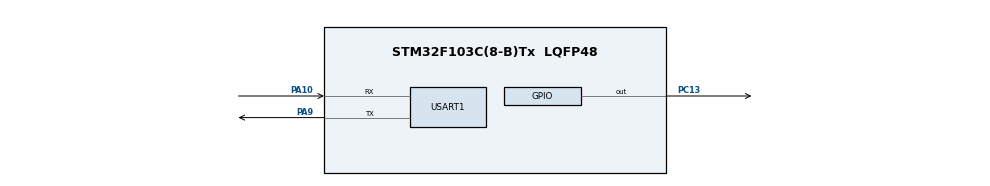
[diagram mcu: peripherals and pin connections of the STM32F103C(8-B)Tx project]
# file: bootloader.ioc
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Mcu.Family=STM32F1
Mcu.Name=STM32F103C(8-B)Tx
Mcu.Package=LQFP48
NVIC.PriorityGroup=NVIC_PRIORITYGROUP_4
PA10.Mode=Asynchronous
PA10.Signal=USART1_RX
PA13.Mode=Serial_Wire
PA13.Signal=SYS_JTMS-SWDIO
PA14.Mode=Serial_Wire
PA14.Signal=SYS_JTCK-SWCLK
PA9.Mode=Asynchronous
PA9.Signal=USART1_TX
PC13-TAMPER-RTC.Signal=GPIO_Output
ProjectManager.HeapSize=0x200
ProjectManager.StackSize=0x400
ProjectManager.TargetToolchain=Makefile
RCC.APB1Freq_Value=8000000
RCC.APB2Freq_Value=8000000
USART1.VirtualMode=VM_ASYNC
board=custom

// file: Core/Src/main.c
/* USER CODE BEGIN Header */
/**
 ******************************************************************************
 * @file           : main.c
 * @brief          : Main program body
 ******************************************************************************
 * @attention
 *
 * Copyright (c) 2026 STMicroelectronics.
 * All rights reserved.
 *
 * This software is licensed under terms that can be found in the LICENSE file
 * in the root directory of this software component.
 * If no LICENSE file comes with this software, it is provided AS-IS.
 *
 ******************************************************************************
 */
/* USER CODE END Header */
#include "main.h"

/* USER CODE BEGIN Includes */
#include "string.h"
/* USER CODE END Includes */

UART_HandleTypeDef huart1;

void SystemClock_Config(void);
static void MX_GPIO_Init(void);
static void MX_USART1_UART_Init(void);

/* USER CODE BEGIN 0 */
#define APP_PROGRAM_ADDRESS 0x08002000
typedef void (*pFunction)(void);

void enterApplication(void) {
    // uint32_t appStack = *(__IO uint32_t *)APP_PROGRAM_ADDRESS;
    pFunction appEntry = (pFunction)(*(__IO uint32_t *)(APP_PROGRAM_ADDRESS + 4));

    HAL_DeInit();
    HAL_RCC_DeInit();

    SCB->SHCSR &= ~(SCB_SHCSR_MEMFAULTENA_Msk | SCB_SHCSR_BUSFAULTENA_Msk | SCB_SHCSR_USGFAULTENA_Msk);

    __set_MSP(*(__IO uint32_t *)APP_PROGRAM_ADDRESS);

    appEntry();
}

uint16_t simpleChecksum(uint8_t *data, uint16_t length) {
    uint16_t checksum = 0;
    for (uint16_t i = 0; i < length; i++) {
        checksum += data[i];
    }
    return checksum;
}

#define START_PAGE 8
#define END_PAGE 127

#define START_BYTE 0xAA
#define ACK 0xCC
#define NACK 0x33
#define BLOCK_SIZE 256

void sendByte(uint8_t byte) {
    HAL_UART_Transmit(&huart1, &byte, 1, 1000);
}

uint8_t receiveByte(uint8_t *byteBuffer, uint16_t size, uint16_t timeout) {
    return HAL_UART_Receive(&huart1, byteBuffer, size, timeout);
}

uint8_t header[3];
uint8_t data[BLOCK_SIZE];
uint8_t checksum[2];

void bootloaderTask() {
    memset(header, 0, sizeof(header));
    uint32_t app_address = APP_PROGRAM_ADDRESS;

    // HAL_Delay(100000);
    flash_erase(APP_PROGRAM_ADDRESS, 50);
    // HAL_Delay(100000);
    while (1) {
        if (receiveByte(&header[0], 1, 5000) != HAL_OK || header[0] != START_BYTE)
            continue;
        if (receiveByte(&header[1], 2, 1000) != HAL_OK) {
            sendByte(NACK);
            continue;
        }

        uint16_t length = (header[1] << 8) | header[2];
        if (length > BLOCK_SIZE) {
            sendByte(NACK);
            continue;
        }

        if (length == 0) {
            sendByte(ACK);
            break;
        }

        if (receiveByte(data, length, 2000) != HAL_OK) {
            sendByte(NACK);
            continue;
        }

        if (receiveByte(checksum, 2, 1000) != HAL_OK) {
            sendByte(NACK);
            continue;
        }

        uint16_t receivedChecksum = (checksum[0] << 8) | checksum[1];
        uint16_t calculatedChecksum = simpleChecksum(data, length);
        if (receivedChecksum != calculatedChecksum) {
            sendByte(NACK);
            continue;
        }

        flash_write(app_address, data, length);
        app_address += length;

        sendByte(ACK);
    }
}

/* USER CODE END 0 */

int main(void)
{

  /* MCU Configuration--------------------------------------------------------*/

  /* Reset of all peripherals, Initializes the Flash interface and the Systick. */
  HAL_Init();

  /* Configure the system clock */
  SystemClock_Config();

  /* Initialize all configured peripherals */
  MX_GPIO_Init();
  MX_USART1_UART_Init();
  /* USER CODE BEGIN 2 */
    HAL_GPIO_WritePin(GPIOC, GPIO_PIN_13, GPIO_PIN_RESET);
    bootloaderTask();
    HAL_GPIO_WritePin(GPIOC, GPIO_PIN_13, GPIO_PIN_SET);
    enterApplication();
  /* USER CODE END 2 */

  /* Infinite loop */
  /* USER CODE BEGIN WHILE */
    while (1) {
        // HAL_GPIO_WritePin(GPIOC, GPIO_PIN_13, GPIO_PIN_RESET);
        // HAL_Delay(1000);

        // enterApplication();
        // HAL_Delay(100);
    /* USER CODE END WHILE */

    }
}

void SystemClock_Config(void)
{
  RCC_OscInitTypeDef RCC_OscInitStruct = {0};
  RCC_ClkInitTypeDef RCC_ClkInitStruct = {0};

  /** Initializes the RCC Oscillators according to the specified parameters
  * in the RCC_OscInitTypeDef structure.
  */
  RCC_OscInitStruct.OscillatorType = RCC_OSCILLATORTYPE_HSI;
  RCC_OscInitStruct.HSIState = RCC_HSI_ON;
  RCC_OscInitStruct.HSICalibrationValue = RCC_HSICALIBRATION_DEFAULT;
  RCC_OscInitStruct.PLL.PLLState = RCC_PLL_NONE;
  if (HAL_RCC_OscConfig(&RCC_OscInitStruct) != HAL_OK)
  {
    Error_Handler();
  }

  /** Initializes the CPU, AHB and APB buses clocks
  */
  RCC_ClkInitStruct.ClockType = RCC_CLOCKTYPE_HCLK|RCC_CLOCKTYPE_SYSCLK
                              |RCC_CLOCKTYPE_PCLK1|RCC_CLOCKTYPE_PCLK2;
  RCC_ClkInitStruct.SYSCLKSource = RCC_SYSCLKSOURCE_HSI;
  RCC_ClkInitStruct.AHBCLKDivider = RCC_SYSCLK_DIV1;
  RCC_ClkInitStruct.APB1CLKDivider = RCC_HCLK_DIV1;
  RCC_ClkInitStruct.APB2CLKDivider = RCC_HCLK_DIV1;

  if (HAL_RCC_ClockConfig(&RCC_ClkInitStruct, FLASH_LATENCY_0) != HAL_OK)
  {
    Error_Handler();
  }
}

static void MX_USART1_UART_Init(void)
{

  huart1.Instance = USART1;
  huart1.Init.BaudRate = 115200;
  huart1.Init.WordLength = UART_WORDLENGTH_8B;
  huart1.Init.StopBits = UART_STOPBITS_1;
  huart1.Init.Parity = UART_PARITY_NONE;
  huart1.Init.Mode = UART_MODE_TX_RX;
  huart1.Init.HwFlowCtl = UART_HWCONTROL_NONE;
  huart1.Init.OverSampling = UART_OVERSAMPLING_16;
  if (HAL_UART_Init(&huart1) != HAL_OK)
  {
    Error_Handler();
  }

}

static void MX_GPIO_Init(void)
{
  GPIO_InitTypeDef GPIO_InitStruct = {0};

  /* GPIO Ports Clock Enable */
  __HAL_RCC_GPIOC_CLK_ENABLE();
  __HAL_RCC_GPIOA_CLK_ENABLE();

  /*Configure GPIO pin Output Level */
  HAL_GPIO_WritePin(GPIOC, GPIO_PIN_13, GPIO_PIN_RESET);

  /*Configure GPIO pin : PC13 */
  GPIO_InitStruct.Pin = GPIO_PIN_13;
  GPIO_InitStruct.Mode = GPIO_MODE_OUTPUT_PP;
  GPIO_InitStruct.Pull = GPIO_NOPULL;
  GPIO_InitStruct.Speed = GPIO_SPEED_FREQ_LOW;
  HAL_GPIO_Init(GPIOC, &GPIO_InitStruct);

}

void Error_Handler(void)
{
    __disable_irq();
    while (1) {
    }
}
